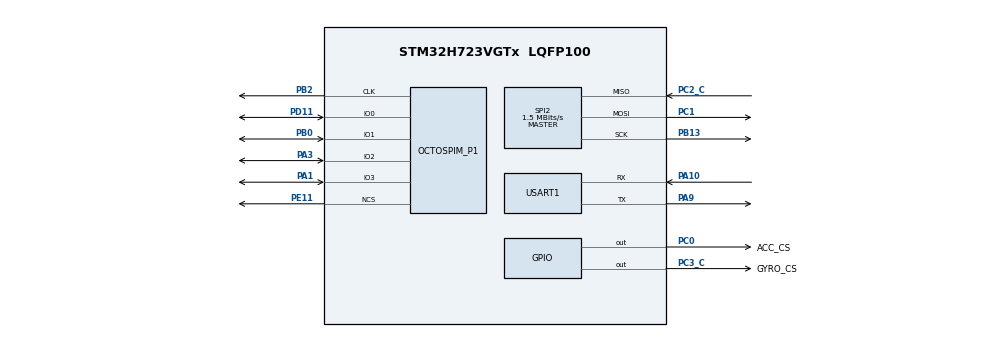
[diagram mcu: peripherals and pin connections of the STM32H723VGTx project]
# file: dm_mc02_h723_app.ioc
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Dma.Request0=USART1_RX
Dma.Request1=USART1_TX
Dma.USART1_RX.0.Direction=DMA_PERIPH_TO_MEMORY
Dma.USART1_RX.0.EventEnable=DISABLE
Dma.USART1_RX.0.FIFOMode=DMA_FIFOMODE_DISABLE
Dma.USART1_RX.0.Instance=DMA1_Stream0
Dma.USART1_RX.0.MemDataAlignment=DMA_MDATAALIGN_BYTE
Dma.USART1_RX.0.MemInc=DMA_MINC_ENABLE
Dma.USART1_RX.0.Mode=DMA_CIRCULAR
Dma.USART1_RX.0.PeriphDataAlignment=DMA_PDATAALIGN_BYTE
Dma.USART1_RX.0.PeriphInc=DMA_PINC_DISABLE
Dma.USART1_RX.0.Polarity=HAL_DMAMUX_REQ_GEN_RISING
Dma.USART1_RX.0.Priority=DMA_PRIORITY_MEDIUM
Dma.USART1_RX.0.RequestNumber=1
Dma.USART1_RX.0.SignalID=NONE
Dma.USART1_RX.0.SyncEnable=DISABLE
Dma.USART1_RX.0.SyncPolarity=HAL_DMAMUX_SYNC_NO_EVENT
Dma.USART1_RX.0.SyncRequestNumber=1
Dma.USART1_RX.0.SyncSignalID=NONE
Dma.USART1_TX.1.Direction=DMA_MEMORY_TO_PERIPH
Dma.USART1_TX.1.EventEnable=DISABLE
Dma.USART1_TX.1.FIFOMode=DMA_FIFOMODE_DISABLE
Dma.USART1_TX.1.Instance=DMA1_Stream1
Dma.USART1_TX.1.MemDataAlignment=DMA_MDATAALIGN_BYTE
Dma.USART1_TX.1.MemInc=DMA_MINC_ENABLE
Dma.USART1_TX.1.Mode=DMA_NORMAL
Dma.USART1_TX.1.PeriphDataAlignment=DMA_PDATAALIGN_BYTE
Dma.USART1_TX.1.PeriphInc=DMA_PINC_DISABLE
Dma.USART1_TX.1.Polarity=HAL_DMAMUX_REQ_GEN_RISING
Dma.USART1_TX.1.Priority=DMA_PRIORITY_MEDIUM
Dma.USART1_TX.1.RequestNumber=1
Dma.USART1_TX.1.SignalID=NONE
Dma.USART1_TX.1.SyncEnable=DISABLE
Dma.USART1_TX.1.SyncPolarity=HAL_DMAMUX_SYNC_NO_EVENT
Dma.USART1_TX.1.SyncRequestNumber=1
Dma.USART1_TX.1.SyncSignalID=NONE
Mcu.Family=STM32H7
Mcu.Name=STM32H723VGTx
Mcu.Package=LQFP100
NVIC.DMA1_Stream0_IRQn=true\:0\:0\:false\:false\:true\:false\:true\:true
NVIC.DMA1_Stream1_IRQn=true\:0\:0\:false\:false\:true\:false\:true\:true
NVIC.PriorityGroup=NVIC_PRIORITYGROUP_4
NVIC.USART1_IRQn=true\:0\:0\:false\:false\:true\:true\:true\:true
OCTOSPI1.ClockPrescaler=4
PA1.Mode=OCTOSPI1_IOL_Port1L
PA1.Signal=OCTOSPIM_P1_IO3
PA10.Mode=Asynchronous
PA10.Signal=USART1_RX
PA13(JTMS/SWDIO).Mode=Serial_Wire
PA13(JTMS/SWDIO).Signal=DEBUG_JTMS-SWDIO
PA14(JTCK/SWCLK).Mode=Serial_Wire
PA14(JTCK/SWCLK).Signal=DEBUG_JTCK-SWCLK
PA3.Mode=OCTOSPI1_IOL_Port1L
PA3.Signal=OCTOSPIM_P1_IO2
PA9.Mode=Asynchronous
PA9.Signal=USART1_TX
PB0.Mode=OCTOSPI1_IOL_Port1L
PB0.Signal=OCTOSPIM_P1_IO1
PB13.Mode=Full_Duplex_Master
PB13.Signal=SPI2_SCK
PB2.Mode=O1_P1_CLK
PB2.Signal=OCTOSPIM_P1_CLK
PC0.GPIO_Label=ACC_CS
PC0.GPIO_Speed=GPIO_SPEED_FREQ_HIGH
PC0.PinState=GPIO_PIN_SET
PC0.Signal=GPIO_Output
PC1.Mode=Full_Duplex_Master
PC1.Signal=SPI2_MOSI
PC2_C.Mode=Full_Duplex_Master
PC2_C.Signal=SPI2_MISO
PC3_C.GPIO_Label=GYRO_CS
PC3_C.GPIO_ModeDefaultOutputPP=GPIO_MODE_OUTPUT_PP
PC3_C.GPIO_Speed=GPIO_SPEED_FREQ_HIGH
PC3_C.PinState=GPIO_PIN_SET
PC3_C.Signal=GPIO_Output
PD11.Mode=OCTOSPI1_IOL_Port1L
PD11.Signal=OCTOSPIM_P1_IO0
PE11.Mode=OCTOSPI1_Port1_NCS
PE11.Signal=OCTOSPIM_P1_NCS
PH0-OSC_IN.Mode=HSE-External-Oscillator
PH0-OSC_IN.Signal=RCC_OSC_IN
PH1-OSC_OUT.Mode=HSE-External-Oscillator
PH1-OSC_OUT.Signal=RCC_OSC_OUT
ProjectManager.HeapSize=0x1200
ProjectManager.StackSize=0x400
ProjectManager.TargetToolchain=MDK-ARM V5.32
RCC.ADCFreq_Value=96000000
RCC.APB1Freq_Value=100000000
RCC.APB2Freq_Value=100000000
RCC.APB3Freq_Value=100000000
RCC.APB4Freq_Value=100000000
RCC.CortexFreq_Value=400000000
RCC.D1PPRE=RCC_APB3_DIV2
RCC.D2PPRE1=RCC_APB1_DIV2
RCC.D2PPRE2=RCC_APB2_DIV2
RCC.D3PPRE=RCC_APB4_DIV2
RCC.DIVM1=3
RCC.DIVM2=2
RCC.DIVN1=50
RCC.DIVN2=16
RCC.DIVP1=1
RCC.DIVQ1=3
RCC.HCLKFreq_Value=200000000
RCC.HPRE=RCC_HCLK_DIV2
RCC.HSE_VALUE=24000000
RCC.PLL1_VCI_Range-AdvancedSettings=RCC_PLL1VCIRANGE_0
RCC.PLL2FRACN=0
RCC.PLL3FRACN=0
RCC.PLL3_VCO_SEL-AdvancedSettings=RCC_PLL3VCOWIDE
RCC.PLLFRACN=0
RCC.PLLSourceVirtual=RCC_PLLSOURCE_HSE
RCC.SPI123CLockSelection=RCC_SPI123CLKSOURCE_PLL2
RCC.SYSCLKFreq_VALUE=400000000
RCC.SYSCLKSource=RCC_SYSCLKSOURCE_PLLCLK
RCC.USBFreq_Value=133333333.33333333
SPI2.BaudRatePrescaler=SPI_BAUDRATEPRESCALER_64
SPI2.CalculateBaudRate=1.5 MBits/s
SPI2.DataSize=SPI_DATASIZE_8BIT
SPI2.Direction=SPI_DIRECTION_2LINES
SPI2.Mode=SPI_MODE_MASTER
SPI2.VirtualType=VM_MASTER
USART1.VirtualMode-Asynchronous=VM_ASYNC
VP_OCTOSPI1_VS_quad.Mode=quad_mode
board=custom

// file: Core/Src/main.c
/* USER CODE BEGIN Header */
/**
  ******************************************************************************
  * @file           : main.c
  * @brief          : Main program body
  ******************************************************************************
  * @attention
  *
  * Copyright (c) 2026 STMicroelectronics.
  * All rights reserved.
  *
  * This software is licensed under terms that can be found in the LICENSE file
  * in the root directory of this software component.
  * If no LICENSE file comes with this software, it is provided AS-IS.
  *
  ******************************************************************************
  */
/* USER CODE END Header */
#include "main.h"
#include "dma.h"
#include "octospi.h"
#include "spi.h"
#include "usart.h"
#include "gpio.h"

/* USER CODE BEGIN Includes */

#include "app_main.h"
#include "app_test.h"
/* USER CODE END Includes */

void SystemClock_Config(void);

int main(void)
{

  /* MCU Configuration--------------------------------------------------------*/

  /* Reset of all peripherals, Initializes the Flash interface and the Systick. */
  HAL_Init();

  /* Configure the system clock */
  SystemClock_Config();

  /* Initialize all configured peripherals */
  MX_GPIO_Init();
  MX_DMA_Init();
  MX_USART1_UART_Init();
  MX_SPI2_Init();
  MX_OCTOSPI1_Init();
  /* USER CODE BEGIN 2 */
/* USER CODE BEGIN 2 */
 // App_Init();
	AppTestStreamBlock_Init();
  /* USER CODE END 2 */

  /* Infinite loop */
  /* USER CODE BEGIN WHILE */
  while (1)
  {
     //App_Run();
  AppTestStreamBlock_Run();
    /* USER CODE END WHILE */

  }
}

void SystemClock_Config(void)
{
  RCC_OscInitTypeDef RCC_OscInitStruct = {0};
  RCC_ClkInitTypeDef RCC_ClkInitStruct = {0};

  /** Supply configuration update enable
  */
  HAL_PWREx_ConfigSupply(PWR_LDO_SUPPLY);

  /** Configure the main internal regulator output voltage
  */
  __HAL_PWR_VOLTAGESCALING_CONFIG(PWR_REGULATOR_VOLTAGE_SCALE1);

  while(!__HAL_PWR_GET_FLAG(PWR_FLAG_VOSRDY)) {}

  /** Initializes the RCC Oscillators according to the specified parameters
  * in the RCC_OscInitTypeDef structure.
  */
  RCC_OscInitStruct.OscillatorType = RCC_OSCILLATORTYPE_HSE;
  RCC_OscInitStruct.HSEState = RCC_HSE_ON;
  RCC_OscInitStruct.PLL.PLLState = RCC_PLL_ON;
  RCC_OscInitStruct.PLL.PLLSource = RCC_PLLSOURCE_HSE;
  RCC_OscInitStruct.PLL.PLLM = 3;
  RCC_OscInitStruct.PLL.PLLN = 50;
  RCC_OscInitStruct.PLL.PLLP = 1;
  RCC_OscInitStruct.PLL.PLLQ = 3;
  RCC_OscInitStruct.PLL.PLLR = 2;
  RCC_OscInitStruct.PLL.PLLRGE = RCC_PLL1VCIRANGE_3;
  RCC_OscInitStruct.PLL.PLLVCOSEL = RCC_PLL1VCOWIDE;
  RCC_OscInitStruct.PLL.PLLFRACN = 0;
  if (HAL_RCC_OscConfig(&RCC_OscInitStruct) != HAL_OK)
  {
    Error_Handler();
  }

  /** Initializes the CPU, AHB and APB buses clocks
  */
  RCC_ClkInitStruct.ClockType = RCC_CLOCKTYPE_HCLK|RCC_CLOCKTYPE_SYSCLK
                              |RCC_CLOCKTYPE_PCLK1|RCC_CLOCKTYPE_PCLK2
                              |RCC_CLOCKTYPE_D3PCLK1|RCC_CLOCKTYPE_D1PCLK1;
  RCC_ClkInitStruct.SYSCLKSource = RCC_SYSCLKSOURCE_PLLCLK;
  RCC_ClkInitStruct.SYSCLKDivider = RCC_SYSCLK_DIV1;
  RCC_ClkInitStruct.AHBCLKDivider = RCC_HCLK_DIV2;
  RCC_ClkInitStruct.APB3CLKDivider = RCC_APB3_DIV2;
  RCC_ClkInitStruct.APB1CLKDivider = RCC_APB1_DIV2;
  RCC_ClkInitStruct.APB2CLKDivider = RCC_APB2_DIV2;
  RCC_ClkInitStruct.APB4CLKDivider = RCC_APB4_DIV2;

  if (HAL_RCC_ClockConfig(&RCC_ClkInitStruct, FLASH_LATENCY_2) != HAL_OK)
  {
    Error_Handler();
  }
}

void Error_Handler(void)
{
  __disable_irq();
  while (1)
  {
  }
}
